# RL7005_IP_SVD register map
Vendor: Realtek
Registers are 32-bit, read-write, reset 0x0 unless marked. A register's access mark holds for its fields unless they carry their own. Offsets are from the block's base; [hi:lo] are bit positions.

## LDO_REG
Base 0x4080A100
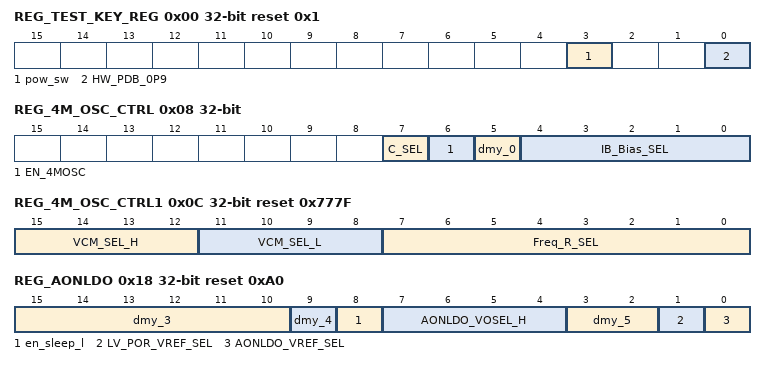
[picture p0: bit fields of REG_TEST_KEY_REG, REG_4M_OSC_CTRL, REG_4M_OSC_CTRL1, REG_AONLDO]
0x00 REG_TEST_KEY_REG reset 0x1
  [3] pow_sw — power swr
  [0] HW_PDB_0P9 — // 此訊號,務必正確的default value // Digital 送此訊號透過analog levelshift到HW_PDB_33V_OUT // level shift gating to low by POR_AON
0x04 REG_RF_EN_dummy
  [0] REG_POW_4MOSC — // [RF][4MOSC] dummy
0x08 REG_4M_OSC_CTRL access per field
  [7] C_SEL rw — // [RF][4MOSC] REG_CTRL
  [6] EN_4MOSC ro — // [RF][4MOSC] 1'b1 : enable
  [5] dmy_0 rw — // [RF][4MOSC] REG_CTRL
  [4:0] IB_Bias_SEL rw — // [RF][4MOSC] REG_CTRL
0x0C REG_4M_OSC_CTRL1 reset 0x777F
  [15:12] VCM_SEL_H — // [RF][4MOSC] REG_CTRL
  [11:8] VCM_SEL_L — // [RF][4MOSC] REG_CTRL
  [7:0] Freq_R_SEL — // [RF][4MOSC] REG_CTRL
0x18 REG_AONLDO reset 0xA0
  [15:10] dmy_3 — // [REGU][AONLDO] dummy
  [9] dmy_4 — // [REGU][AONLDO] dummy
  [8] en_sleep_l — Enable LDO09H sleep mode 0 : disable (default) 1 : enable
  [7:4] AONLDO_VOSEL_H — AONLDO09 voltage select 0000: 0.528V 0.464V 0001: 0.630V 0.554V 0010: 0.659V 0.579V 0011: 0.690V 0.606V 0100: 0.724V 0.636V 0101: 0.742V 0.652V 0110: 0.761V 0.669V 0111: 0.782V 0.687V 1000: 0.803V 0.706V 1001: 0.826V 0.725V 1010: 0.850V 0.746V 1011: 0.875V 0.769V 1100: 0.902V 0.792V 1101: 0.930V 0.817V 1110: 0.960V 0.844V 1111: 0.993V 0.872V
  [3:2] dmy_5 — // [REGU][AONLDO] dummy
  [1] LV_POR_VREF_SEL — LV_POR VREF 0 (default) VREF = 0P600V 1 VREF = 0P450V
  [0] AONLDO_VREF_SEL — AONLDO VREF_SEL 0 (default) VREF = 0P600V 1 VREF = 0P575V
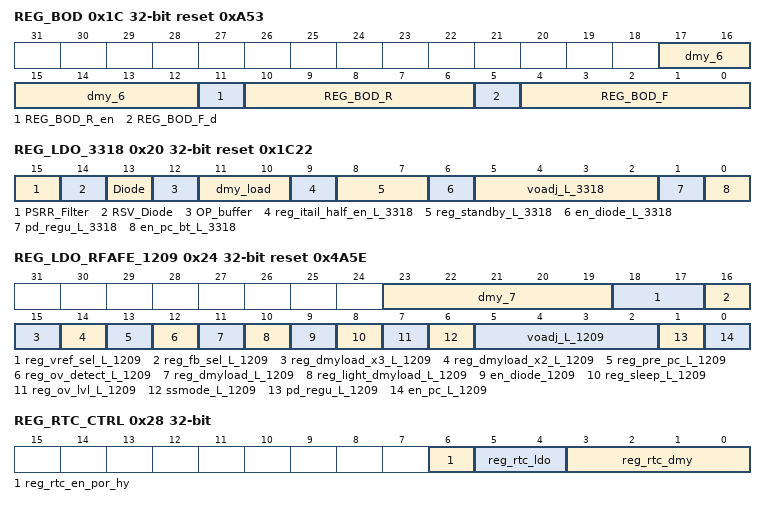
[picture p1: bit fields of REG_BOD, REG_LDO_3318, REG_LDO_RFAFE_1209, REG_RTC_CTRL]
0x1C REG_BOD reset 0xA53
  [17:12] dmy_6 — // dummy)
  [11] REG_BOD_R_en — // 0: disable BOD // 1: enable BOD
  [10:6] REG_BOD_R — 00000:3.3333 00001:3.2877 00010:3.2432 00011:3.2000 00100:3.1579 00101:3.1035 00110:3.0508 00111:3.0000 01000:2.9508 01001:2.9032 01010:2.8571 01011:2.8125 01100:2.7692 01101:2.7169 01110:2.6666 01111:2.6182 10000:2.5623 10001:2.5087 10010:2.4574 10011:2.4080 10100:2.3606 10101:2.3151 10110:2.2713 10111:2.2154 11000:2.1621 11001:2.1114 11010:2.0630 11011:2.0168 11100:1.9672 11101:1.9098 11110:1.8556 11111:1.8045
  [5] REG_BOD_F_d — // dummy
  [4:0] REG_BOD_F — 00000:3.3333 00001:3.2877 00010:3.2432 00011:3.2000 00100:3.1579 00101:3.1035 00110:3.0508 00111:3.0000 01000:2.9508 01001:2.9032 01010:2.8571 01011:2.8125 01100:2.7692 01101:2.7169 01110:2.6666 01111:2.6182 10000:2.5623 10001:2.5087 10010:2.4574 10011:2.4080 10100:2.3606 10101:2.3151 10110:2.2713 10111:2.2154 11000:2.1621 11001:2.1114 11010:2.0630 11011:2.0168 11100:1.9672 11101:1.9098 11110:1.8556 11111:1.8045
0x20 REG_LDO_3318 access per field reset 0x1C22
  [15] PSRR_Filter rw — 0: disable PSRR Filter 1: enable PSRR Filter
  [14] RSV_Diode rw — 0: disable rsv diode 1: enable rsv diode
  [13] Diode rw — 0: disable force diode 1: enable force diode
  [12] OP_buffer rw — 0: PMOS buffer 1: NMOS buffer
  [11:10] dmy_load rw — 00:0mA 01:200kΩ 10:183Ω 11:183Ω||200kΩ Note:this field controlled by syson pmc. When pmc require dummy on , and this field indicate dummy resident. When pmc require dummy off , this field has no means, analog will see load is 0 When mldo_tmode is assert , pmc controller is not active
  [9] reg_itail_half_en_L_3318 rw — // [REGU][LDO_UART] REG_CTRL // LDO iq half ctrl // 0(default): iq normal (for normal mode) // 1: iq half (for suspend mode)
  [8:7] reg_standby_L_3318 rw — //11: iq=1.5uA; load=1mA~10mA (sleep) //10: iq=45uA; load=10mA(Start Up) (normal-0) //00: iq=45uA; load=5mA~160mA (normal-1) Note:this field controlled by syson pmc. When pmc require mode > 0 , and this field indicate pmc request. When pmc require mode is 0, this field has no use When mldo_tmode is assert , pmc controller is not active
  [6] en_diode_L_3318 rw — // [REGU][LDO_UART] REG_CTRL // PGATE diode clamp (this gating to disable by pd_regu_L) // 0: disable clamp // 1: enable clamp (default)
  [5:2] voadj_L_3318 ro — // [REGU][LDO_UART] REG_CTRL // LDO VOSEL // 0000, 0001, 0010, 0011: 1.655, 1.672, 1.690, 1.708 // 0100, 0101, 0110, 0111: 1.727, 1.745, 1.764, 1.784 // 1000, 1001(default), 1010, 1011: 1.804, 1.825, 1.846, 1.868 // 1100, 1101, 1110, 1111: 1.890, 1.912, 1.935, 1.959 Note: the acture write-able addr move to 0x4C[23:20] for otp program easy
  [1] pd_regu_L_3318 rw — // [REGU][LDO_UART] REG_CTRL // PowerDown CTRL // 0: normal-Mode(default) // 1: power-down Mode Note: This field is also controlled by syson pmc . When mldo_tmode is assert , pmc controller is not active
  [0] en_pc_bt_L_3318 rw — // [REGU][LDO] REG_CTRL // PWRCUT enable // 0: LDO-Mode (default) // 1: PWRCUT-Mode
0x24 REG_LDO_RFAFE_1209 access per field reset 0x4A5E
  [23:19] dmy_7 rw — Dummy
  [18:17] reg_vref_sel_L_1209 rw — // [REGU][LDO] REG_CTRL // vref sel // 00: 0.6V // 01: 0.57V // 10: 0.56V // 11: 0.54V
  [16] reg_fb_sel_L_1209 rw — // [REGU][LDO] REG_CTRL // vo feedback select // 0: vo(digital pad) (default) // 1: vo_18(powermos pad)
  [15] reg_dmyload_x3_L_1209 rw — // [REGU][LDO] REG_CTRL // LDO dmy load ctrl // 0: dmyload_1X(5mA) // 1: dmyload_3X(15mA)
  [14] reg_dmyload_x2_L_1209 rw — // [REGU][LDO] REG_CTRL // LDO dmy load ctrl // 0: dmyload_1X(5mA) // 1: dmyload_2X(10mA)
  [13] reg_pre_pc_L_1209 rw — // [REGU][LDO] REG_CTRL // 0: LDO-Mode (default) // 1:Pre- PWRCUT-Mode
  [12] reg_ov_detect_L_1209 rw — // [REGU][LDO] REG_CTRL // OV detect function control // 0: disable // 1 : enable
  [11] reg_dmyload_L_1209 ro — // [REGU][LDO] REG_CTRL // LDO dmy load ctrl // 0: dmy load disable // 1: dmy load enable
  [10] reg_light_dmyload_L_1209 rw — // [REGU][LDO] REG_CTRL // LDO dmy load ctrl // 0: dmy load disable // 1:9k Ω (0.1mA)
  [9] en_diode_1209 rw — // [REGU][LDO] REG_CTRL // PGATE diode clamp (this gating to disable by pd_regu_L) // 1: enable clamp // 0: disable clamp
  [8] reg_sleep_L_1209 rw — // [REGU][LDO] REG_CTRL // LDO mode control // 0: normal mode // 1 : sleep mode
  [7] reg_ov_lvl_L_1209 rw — // [REGU][LDO] REG_CTRL // OV vref level // 0: 1.05V // 1 : 1V
  [6] ssmode_L_1209 rw — //0:disable ssmode function //1:enable: ssmode function (smaller power mos size)
  [5:2] voadj_L_1209 rw — // [REGU][LDO] REG_CTRL // LDO VOSEL // 0000, 0001, 0010, 0011: 0.708, 0.739, 0.772, 0.802 // 0100, 0101, 0110, 0111(default): 0.827, 0.853, 0.877, 0.9 // 1000, 1001, 1010, 1011: 0.924, 0.949, 0.976, 1 // 1100, 1101, 1110, 1111: 1.025, 1.05, 1.075, 1.01
  [1] pd_regu_L_1209 rw — // [REGU][LDO] REG_CTRL // PowerDown CTRL // 0: normal-Mode // 1: power-down Mode (default)
  [0] en_pc_L_1209 rw — // [REGU][LDO] REG_CTRL // PWRCUT enable // 0: LDO-Mode (default) // 1: PWRCUT-Mode
0x28 REG_RTC_CTRL
  [6] reg_rtc_en_por_hy, [5:4] reg_rtc_ldo, [3:0] reg_rtc_dmy
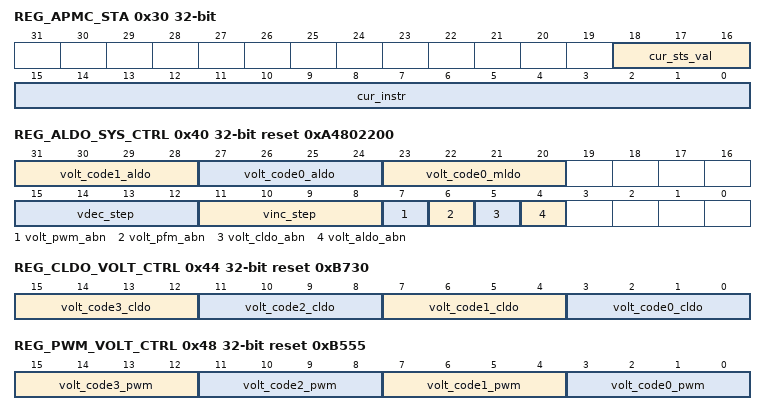
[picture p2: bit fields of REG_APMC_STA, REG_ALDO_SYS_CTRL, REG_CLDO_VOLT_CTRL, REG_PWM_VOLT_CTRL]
0x30 REG_APMC_STA ro
  [18:16] cur_sts_val — current regu status
  [15:0] cur_instr — regu pmc current instruction code
0x34 REG_APMC_VEC ro
  [15:0] cur_vec — regu pmc all intr vector
0x38 REG_APMC_ISR ro
  [15:0] cur_isr — regu pmc current processing isr, one hot
0x40 REG_ALDO_SYS_CTRL access per field reset 0xA4802200
  [31:28] volt_code1_aldo rw — Aon LDO code1 , which indicate 0.8v
  [27:24] volt_code0_aldo rw — Aon LDO code0 , which indicate 0.7v
  [23:20] volt_code0_mldo rw — Mem LDO code0 , which indicate 1.8v
  [15:12] vdec_step rw — volt decrease step , unit in 100K cycle, acture value is this value + 1 Note: this is common for all LDO and SWR
  [11:8] vinc_step rw — volt decrease step , unit in 100K cycle, acture value is this value + 1 Note: this is common for all LDO and SWR
  [7] volt_pwm_abn ro — pwm volt adject abnormal statue . When happen , it is means current voltage is higher than request in a rising commond, same as falling case.
  [6] volt_pfm_abn ro — same as [7]
  [5] volt_cldo_abn ro — same as [7]
  [4] volt_aldo_abn ro — same as [7]
0x44 REG_CLDO_VOLT_CTRL reset 0xB730
  [15:12] volt_code3_cldo — Core LDO code3 , which indicate 1.0v
  [11:8] volt_code2_cldo — Core LDO code2 , which indicate 0.9v
  [7:4] volt_code1_cldo — Core LDO code1 , which indicate 0.8v
  [3:0] volt_code0_cldo — Core LDO code0 , which indicate 0.7v , used in power cut mode
0x48 REG_PWM_VOLT_CTRL reset 0xB555
  [15:12] volt_code3_pwm — SWR pwm volt code3 , which indicate 1.35v (for system in 1.0v)
  [11:8] volt_code2_pwm — SWR pwm volt code2 , which indicate 1.25v (for system in 0.9v, snooze also use) Note:code2/code3 , pwm_vref_sel must set 11(default)
  [7:4] volt_code1_pwm — NO use
  [3:0] volt_code0_pwm — SWR pwm volt code0 , which indicate 0.8v (used for snooze mode , at this time , CLDO is in PC mode) Note:vref must change , pwm_vref_sel must set to 00
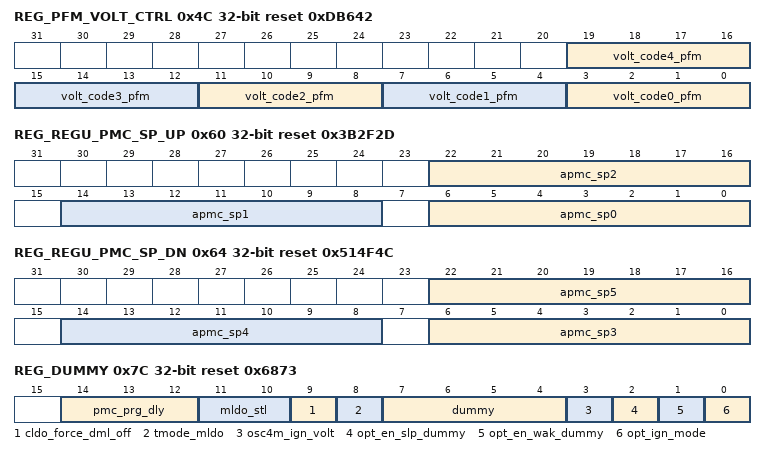
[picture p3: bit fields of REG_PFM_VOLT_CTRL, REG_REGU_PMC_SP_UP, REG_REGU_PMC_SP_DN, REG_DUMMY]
0x4C REG_PFM_VOLT_CTRL reset 0xDB642
  [19:16] volt_code4_pfm — SWR pfm volt code4 , which indicate 1.35v (for system in 1.0v)
  [15:12] volt_code3_pfm — SWR pfm volt code3 , which indicate 1.25v (for system in 0.9v)
  [11:8] volt_code2_pfm — SWR pfm volt code2 , which indicate 0.9v Note:this also used as pre power cut change point
  [7:4] volt_code1_pfm — SWR pfm volt code1 , which indicate 0.8v
  [3:0] volt_code0_pfm — SWR pfm volt code0 , which indicate 0.7v
0x60 REG_REGU_PMC_SP_UP reset 0x3B2F2D
  [22:16] apmc_sp2 — Start Point for ST6 up
  [14:8] apmc_sp1 — Start Point for ST5 up
  [6:0] apmc_sp0 — Start Point for ST3/ST4 up (ST3 not support)
0x64 REG_REGU_PMC_SP_DN reset 0x514F4C
  [22:16] apmc_sp5 — Start Point for ST2 dn , noused
  [14:8] apmc_sp4 — Start Point for ST4/ST3 dn
  [6:0] apmc_sp3 — Start Point for ST5 dn
0x70 REG_DEBUG ro
  [31:0] adbg_regu — REGU interface debug
0x7C REG_DUMMY reset 0x6873
  [14:12] pmc_prg_dly — regu_pmc programmable delay value 0: 100us 1: 500us 2: 1ms 3: 2ms 4: 10ms 5: 50ms 6: 100ms 7: 200ms
  [11:10] mldo_stl — mem LDO power on stable wait time 00: 200us 01: 500us 10: 1ms 11: 2ms
  [9] cldo_force_dml_off — Force core ldo dummy load off , used when pc mode 1: force CLDO dummy load off , regu pmc will wirte this when enter pc mode 0: release
  [8] tmode_mldo — 3318 LDO enter testmode , and register setting will not controlled by pmc
  [7:4] dummy
  [3] osc4m_ign_volt — Options if osc4m can auto require voltage , disable it may speedup reponse time when system never goto 0.7v 0. osc4m will send volt areq when osc4m enable or disable 1. osc4m never req volt change , make sure , system voltage will never goto 0.7v Note: RL6973 never goto 0.7v, fix 1
  [2] opt_en_slp_dummy — option for enable swr dummy load to speed up when pfm voltage falling. Default not enable , using a programmble delay to wait
  [1] opt_en_wak_dummy — option for enable swr dummy load to speed up when pfm -> pwm. if opt_wait_mode is 0 , this bit has no use
  [0] opt_ign_mode — option for ignore regu mode_l wait when pfm -> pwm. default not wait as usual
